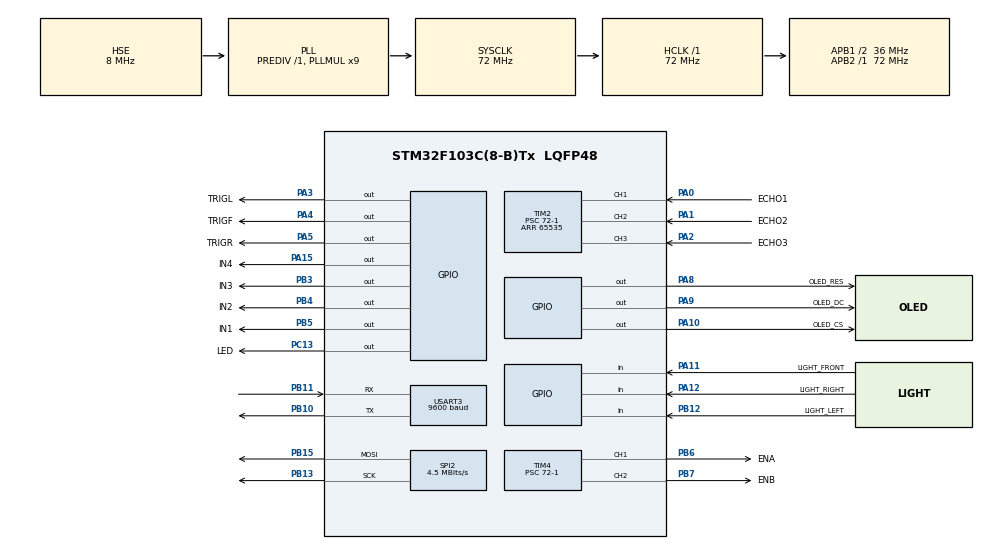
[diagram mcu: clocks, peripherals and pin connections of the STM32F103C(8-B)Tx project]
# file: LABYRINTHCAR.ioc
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Dma.Request0=TIM4_CH1
Dma.Request1=TIM4_CH2
Dma.Request2=USART3_RX
Dma.Request3=USART3_TX
Dma.TIM4_CH1.0.Direction=DMA_MEMORY_TO_PERIPH
Dma.TIM4_CH1.0.Instance=DMA1_Channel1
Dma.TIM4_CH1.0.MemDataAlignment=DMA_MDATAALIGN_HALFWORD
Dma.TIM4_CH1.0.MemInc=DMA_MINC_ENABLE
Dma.TIM4_CH1.0.Mode=DMA_CIRCULAR
Dma.TIM4_CH1.0.PeriphDataAlignment=DMA_PDATAALIGN_HALFWORD
Dma.TIM4_CH1.0.PeriphInc=DMA_PINC_DISABLE
Dma.TIM4_CH1.0.Priority=DMA_PRIORITY_LOW
Dma.TIM4_CH2.1.Direction=DMA_MEMORY_TO_PERIPH
Dma.TIM4_CH2.1.Instance=DMA1_Channel4
Dma.TIM4_CH2.1.MemDataAlignment=DMA_MDATAALIGN_HALFWORD
Dma.TIM4_CH2.1.MemInc=DMA_MINC_ENABLE
Dma.TIM4_CH2.1.Mode=DMA_CIRCULAR
Dma.TIM4_CH2.1.PeriphDataAlignment=DMA_PDATAALIGN_HALFWORD
Dma.TIM4_CH2.1.PeriphInc=DMA_PINC_DISABLE
Dma.TIM4_CH2.1.Priority=DMA_PRIORITY_LOW
Dma.USART3_RX.2.Direction=DMA_PERIPH_TO_MEMORY
Dma.USART3_RX.2.Instance=DMA1_Channel3
Dma.USART3_RX.2.MemDataAlignment=DMA_MDATAALIGN_BYTE
Dma.USART3_RX.2.MemInc=DMA_MINC_ENABLE
Dma.USART3_RX.2.Mode=DMA_CIRCULAR
Dma.USART3_RX.2.PeriphDataAlignment=DMA_PDATAALIGN_BYTE
Dma.USART3_RX.2.PeriphInc=DMA_PINC_DISABLE
Dma.USART3_RX.2.Priority=DMA_PRIORITY_LOW
Dma.USART3_TX.3.Direction=DMA_MEMORY_TO_PERIPH
Dma.USART3_TX.3.Instance=DMA1_Channel2
Dma.USART3_TX.3.MemDataAlignment=DMA_MDATAALIGN_BYTE
Dma.USART3_TX.3.MemInc=DMA_MINC_ENABLE
Dma.USART3_TX.3.Mode=DMA_CIRCULAR
Dma.USART3_TX.3.PeriphDataAlignment=DMA_PDATAALIGN_BYTE
Dma.USART3_TX.3.PeriphInc=DMA_PINC_DISABLE
Dma.USART3_TX.3.Priority=DMA_PRIORITY_LOW
FREERTOS.Tasks01=Init,3,128,Init_Task,As weak,NULL,Dynamic,NULL,NULL;Measuredist,3,128,Measuredist_Task,As weak,NULL,Dynamic,NULL,NULL;OLED,3,128,OLED_Task,As weak,NULL,Dynamic,NULL,NULL;Movecontrol,3,128,Movecontrol_Task,As weak,NULL,Dynamic,NULL,NULL;LIGHT_TEST,3,128,LIGHT_TEST_TASK,As weak,NULL,Dynamic,NULL,NULL
FREERTOS.configTOTAL_HEAP_SIZE=6144
Mcu.Family=STM32F1
Mcu.Name=STM32F103C(8-B)Tx
Mcu.Package=LQFP48
NVIC.DMA1_Channel1_IRQn=true\:5\:0\:false\:false\:true\:true\:false\:true\:true
NVIC.DMA1_Channel2_IRQn=true\:5\:0\:false\:false\:true\:true\:false\:true\:true
NVIC.DMA1_Channel3_IRQn=true\:5\:0\:false\:false\:true\:true\:false\:true\:true
NVIC.DMA1_Channel4_IRQn=true\:5\:0\:false\:false\:true\:true\:false\:true\:true
NVIC.PriorityGroup=NVIC_PRIORITYGROUP_4
NVIC.TIM1_UP_IRQn=true\:15\:0\:false\:false\:true\:false\:false\:true\:true
NVIC.TIM2_IRQn=true\:5\:0\:false\:false\:true\:true\:true\:true\:true
NVIC.TimeBase=TIM1_UP_IRQn
NVIC.TimeBaseIP=TIM1
NVIC.USART3_IRQn=true\:5\:0\:false\:false\:true\:true\:true\:true\:true
PA0-WKUP.GPIO_Label=ECHO1
PA0-WKUP.Signal=S_TIM2_CH1_ETR
PA1.GPIO_Label=ECHO2
PA1.Signal=S_TIM2_CH2
PA10.GPIO_Label=OLED_CS
PA10.PinState=GPIO_PIN_SET
PA10.Signal=GPIO_Output
PA11.GPIO_Label=LIGHT_FRONT
PA11.GPIO_PuPd=GPIO_PULLUP
PA11.Signal=GPIO_Input
PA12.GPIO_Label=LIGHT_RIGHT
PA12.GPIO_PuPd=GPIO_PULLUP
PA12.Signal=GPIO_Input
PA13.Mode=Serial_Wire
PA13.Signal=SYS_JTMS-SWDIO
PA14.Mode=Serial_Wire
PA14.Signal=SYS_JTCK-SWCLK
PA15.GPIO_Label=IN4
PA15.Signal=GPIO_Output
PA2.GPIO_Label=ECHO3
PA2.Signal=S_TIM2_CH3
PA3.GPIO_Label=TRIGL
PA3.Signal=GPIO_Output
PA4.GPIO_Label=TRIGF
PA4.Signal=GPIO_Output
PA5.GPIO_Label=TRIGR
PA5.Signal=GPIO_Output
PA8.GPIO_Label=OLED_RES
PA8.GPIO_Speed=GPIO_SPEED_FREQ_LOW
PA8.PinState=GPIO_PIN_SET
PA8.Signal=GPIO_Output
PA9.GPIO_Label=OLED_DC
PA9.PinState=GPIO_PIN_SET
PA9.Signal=GPIO_Output
PB10.Mode=Asynchronous
PB10.Signal=USART3_TX
PB11.Mode=Asynchronous
PB11.Signal=USART3_RX
PB12.GPIO_Label=LIGHT_LEFT
PB12.GPIO_PuPd=GPIO_PULLUP
PB12.Signal=GPIO_Input
PB13.Mode=TX_Only_Simplex_Unidirect_Master
PB13.Signal=SPI2_SCK
PB15.Mode=TX_Only_Simplex_Unidirect_Master
PB15.Signal=SPI2_MOSI
PB3.GPIO_Label=IN3
PB3.Signal=GPIO_Output
PB4.GPIO_Label=IN2
PB4.Signal=GPIO_Output
PB5.GPIO_Label=IN1
PB5.Signal=GPIO_Output
PB6.GPIO_Label=ENA
PB6.Signal=S_TIM4_CH1
PB7.GPIO_Label=ENB
PB7.Signal=S_TIM4_CH2
PC13-TAMPER-RTC.GPIO_Label=LED
PC13-TAMPER-RTC.Signal=GPIO_Output
PD0-OSC_IN.Mode=HSE-External-Oscillator
PD0-OSC_IN.Signal=RCC_OSC_IN
PD1-OSC_OUT.Mode=HSE-External-Oscillator
PD1-OSC_OUT.Signal=RCC_OSC_OUT
ProjectManager.HeapSize=0x800
ProjectManager.StackSize=0x1000
ProjectManager.TargetToolchain=MDK-ARM V5.32
RCC.AHBFreq_Value=72000000
RCC.APB1CLKDivider=RCC_HCLK_DIV2
RCC.APB1Freq_Value=36000000
RCC.APB1TimFreq_Value=72000000
RCC.APB2Freq_Value=72000000
RCC.APB2TimFreq_Value=72000000
RCC.HCLKFreq_Value=72000000
RCC.PLLMUL=RCC_PLL_MUL9
RCC.PLLSourceVirtual=RCC_PLLSOURCE_HSE
RCC.SYSCLKFreq_VALUE=72000000
RCC.SYSCLKSource=RCC_SYSCLKSOURCE_PLLCLK
RCC.USBFreq_Value=72000000
SH.S_TIM2_CH1_ETR.0=TIM2_CH1,Input_Capture1_from_TI1
SH.S_TIM2_CH2.0=TIM2_CH2,Input_Capture2_from_TI2
SH.S_TIM2_CH3.0=TIM2_CH3,Input_Capture3_from_TI3
SH.S_TIM4_CH1.0=TIM4_CH1,PWM Generation1 CH1
SH.S_TIM4_CH2.0=TIM4_CH2,PWM Generation2 CH2
SPI2.BaudRatePrescaler=SPI_BAUDRATEPRESCALER_8
SPI2.CalculateBaudRate=4.5 MBits/s
SPI2.Direction=SPI_DIRECTION_2LINES
SPI2.Mode=SPI_MODE_MASTER
SPI2.VirtualType=VM_MASTER
TIM2.Channel-Input_Capture1_from_TI1=TIM_CHANNEL_1
TIM2.Channel-Input_Capture2_from_TI2=TIM_CHANNEL_2
TIM2.Channel-Input_Capture3_from_TI3=TIM_CHANNEL_3
TIM2.Period=65535
TIM2.Prescaler=72-1
TIM4.AutoReloadPreload=TIM_AUTORELOAD_PRELOAD_ENABLE
TIM4.Channel-PWM\ Generation1\ CH1=TIM_CHANNEL_1
TIM4.Channel-PWM\ Generation2\ CH2=TIM_CHANNEL_2
TIM4.Period=1000-1
TIM4.Prescaler=72-1
USART3.BaudRate=9600
USART3.VirtualMode=VM_ASYNC
VP_FREERTOS_VS_CMSIS_V1.Mode=CMSIS_V1
VP_SYS_VS_tim1.Mode=TIM1
VP_TIM2_VS_ClockSourceINT.Mode=Internal
VP_TIM4_VS_ClockSourceINT.Mode=Internal
board=custom

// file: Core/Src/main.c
/* USER CODE BEGIN Header */
/**
  ******************************************************************************
  * @file           : main.c
  * @brief          : Main program body
  ******************************************************************************
  * @attention
  *
  * Copyright (c) 2025 STMicroelectronics.
  * All rights reserved.
  *
  * This software is licensed under terms that can be found in the LICENSE file
  * in the root directory of this software component.
  * If no LICENSE file comes with this software, it is provided AS-IS.
  *
  ******************************************************************************
  */
/* USER CODE END Header */
#include "main.h"
#include "cmsis_os.h"
#include "dma.h"
#include "spi.h"
#include "tim.h"
#include "usart.h"
#include "gpio.h"

/* USER CODE BEGIN Includes */
#include "task.h"
/* USER CODE END Includes */

/* USER CODE BEGIN PTD */
//float distance[3]={0};

/* USER CODE END PTD */

void SystemClock_Config(void);
void MX_FREERTOS_Init(void);

int main(void)
{

  /* MCU Configuration--------------------------------------------------------*/

  /* Reset of all peripherals, Initializes the Flash interface and the Systick. */
  HAL_Init();

  /* Configure the system clock */
  SystemClock_Config();

  /* Initialize all configured peripherals */
  MX_GPIO_Init();
  MX_DMA_Init();
  MX_TIM2_Init();
  MX_TIM4_Init();
  MX_SPI2_Init();
  MX_USART3_UART_Init();

  /* Call init function for freertos objects (in cmsis_os2.c) */
  MX_FREERTOS_Init();

  /* Start scheduler */
  osKernelStart();

  /* We should never get here as control is now taken by the scheduler */

  /* Infinite loop */
  while (1)
  {

  }
}

void SystemClock_Config(void)
{
  RCC_OscInitTypeDef RCC_OscInitStruct = {0};
  RCC_ClkInitTypeDef RCC_ClkInitStruct = {0};

  /** Initializes the RCC Oscillators according to the specified parameters
  * in the RCC_OscInitTypeDef structure.
  */
  RCC_OscInitStruct.OscillatorType = RCC_OSCILLATORTYPE_HSE;
  RCC_OscInitStruct.HSEState = RCC_HSE_ON;
  RCC_OscInitStruct.HSEPredivValue = RCC_HSE_PREDIV_DIV1;
  RCC_OscInitStruct.HSIState = RCC_HSI_ON;
  RCC_OscInitStruct.PLL.PLLState = RCC_PLL_ON;
  RCC_OscInitStruct.PLL.PLLSource = RCC_PLLSOURCE_HSE;
  RCC_OscInitStruct.PLL.PLLMUL = RCC_PLL_MUL9;
  if (HAL_RCC_OscConfig(&RCC_OscInitStruct) != HAL_OK)
  {
    Error_Handler();
  }

  /** Initializes the CPU, AHB and APB buses clocks
  */
  RCC_ClkInitStruct.ClockType = RCC_CLOCKTYPE_HCLK|RCC_CLOCKTYPE_SYSCLK
                              |RCC_CLOCKTYPE_PCLK1|RCC_CLOCKTYPE_PCLK2;
  RCC_ClkInitStruct.SYSCLKSource = RCC_SYSCLKSOURCE_PLLCLK;
  RCC_ClkInitStruct.AHBCLKDivider = RCC_SYSCLK_DIV1;
  RCC_ClkInitStruct.APB1CLKDivider = RCC_HCLK_DIV2;
  RCC_ClkInitStruct.APB2CLKDivider = RCC_HCLK_DIV1;

  if (HAL_RCC_ClockConfig(&RCC_ClkInitStruct, FLASH_LATENCY_2) != HAL_OK)
  {
    Error_Handler();
  }
}

void HAL_TIM_PeriodElapsedCallback(TIM_HandleTypeDef *htim)
{
  if (htim->Instance == TIM1) {
    HAL_IncTick();
  }
}

void Error_Handler(void)
{
  __disable_irq();
  while (1)
  {
  }
}

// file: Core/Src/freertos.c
/* USER CODE BEGIN Header */
/**
  ******************************************************************************
  * File Name          : freertos.c
  * Description        : Code for freertos applications
  ******************************************************************************
  * @attention
  *
  * Copyright (c) 2025 STMicroelectronics.
  * All rights reserved.
  *
  * This software is licensed under terms that can be found in the LICENSE file
  * in the root directory of this software component.
  * If no LICENSE file comes with this software, it is provided AS-IS.
  *
  ******************************************************************************
  */
/* USER CODE END Header */

#include "FreeRTOS.h"
#include "task.h"
#include "main.h"
#include "cmsis_os.h"

osThreadId InitHandle;
osThreadId MeasuredistHandle;
osThreadId OLEDHandle;
osThreadId MovecontrolHandle;
osThreadId LIGHT_TESTHandle;

void Init_Task(void const * argument);
void Measuredist_Task(void const * argument);
void OLED_Task(void const * argument);
void Movecontrol_Task(void const * argument);
void LIGHT_TEST_TASK(void const * argument);

void MX_FREERTOS_Init(void); /* (MISRA C 2004 rule 8.1) */

/* GetIdleTaskMemory prototype (linked to static allocation support) */
void vApplicationGetIdleTaskMemory( StaticTask_t **ppxIdleTaskTCBBuffer, StackType_t **ppxIdleTaskStackBuffer, uint32_t *pulIdleTaskStackSize );

/* USER CODE BEGIN GET_IDLE_TASK_MEMORY */
static StaticTask_t xIdleTaskTCBBuffer;
static StackType_t xIdleStack[configMINIMAL_STACK_SIZE];

void vApplicationGetIdleTaskMemory( StaticTask_t **ppxIdleTaskTCBBuffer, StackType_t **ppxIdleTaskStackBuffer, uint32_t *pulIdleTaskStackSize )
{
  *ppxIdleTaskTCBBuffer = &xIdleTaskTCBBuffer;
  *ppxIdleTaskStackBuffer = &xIdleStack[0];
  *pulIdleTaskStackSize = configMINIMAL_STACK_SIZE;
  /* place for user code */
}
/* USER CODE END GET_IDLE_TASK_MEMORY */

void MX_FREERTOS_Init(void) {

  /* Create the thread(s) */
  /* definition and creation of Init */
  osThreadDef(Init, Init_Task, osPriorityRealtime, 0, 128);
  InitHandle = osThreadCreate(osThread(Init), NULL);

  /* definition and creation of Measuredist */
  osThreadDef(Measuredist, Measuredist_Task, osPriorityRealtime, 0, 128);
  MeasuredistHandle = osThreadCreate(osThread(Measuredist), NULL);

  /* definition and creation of OLED */
  osThreadDef(OLED, OLED_Task, osPriorityRealtime, 0, 128);
  OLEDHandle = osThreadCreate(osThread(OLED), NULL);

  /* definition and creation of Movecontrol */
  osThreadDef(Movecontrol, Movecontrol_Task, osPriorityRealtime, 0, 128);
  MovecontrolHandle = osThreadCreate(osThread(Movecontrol), NULL);

  /* definition and creation of LIGHT_TEST */
  osThreadDef(LIGHT_TEST, LIGHT_TEST_TASK, osPriorityRealtime, 0, 128);
  LIGHT_TESTHandle = osThreadCreate(osThread(LIGHT_TEST), NULL);

}

__weak void Init_Task(void const * argument)
{
  for(;;)
  {
    osDelay(1);
  }
}

__weak void Measuredist_Task(void const * argument)
{
  for(;;)
  {
    osDelay(1);
  }
}

__weak void OLED_Task(void const * argument)
{
  for(;;)
  {
    osDelay(1);
  }
}

__weak void Movecontrol_Task(void const * argument)
{
  for(;;)
  {
    osDelay(1);
  }
}

__weak void LIGHT_TEST_TASK(void const * argument)
{
  for(;;)
  {
    osDelay(1);
  }
}
